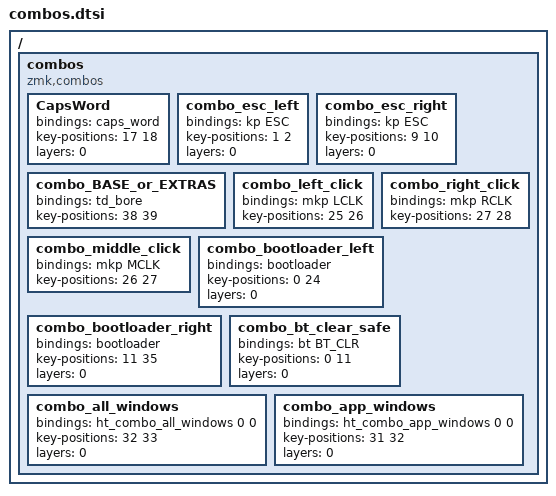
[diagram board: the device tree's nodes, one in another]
/* --- KEY ID LAYOUT --- */
// ╭──────┬──────┬──────┬──────┬──────┬──────╮  ╭──────┬──────┬──────┬──────┬──────┬──────╮
//    00     01     02     03    04      05        06     07     08     09     10     11
// ├──────┼──────┼──────┼──────┼──────┼──────┤  ├──────┼──────┼──────┼──────┼──────┼──────┤
//    12     13     14     15    16      17        18     19     20     21     22     23
// ├──────┼──────┼──────┼──────┼──────┼──────┤  ├──────┼──────┼──────┼──────┼──────┼──────┤
//    24     25     26     27    28      29        30     31     32     33     34     35
// ╰──────┴──────┴──────┼──────┼──────┼──────┤  ├──────┼──────┼──────┴──────┴──────┴──────╯
//                         36     37     38        39     40
//                      ╰──────┴──────┴──────╯  ╰──────┴──────╯

/ {
    combos {
        compatible = "zmk,combos";

        CapsWord {
            bindings = <&caps_word>;
            key-positions = <17 18>;
            layers = <0>;
        };

        combo_esc_left {
            bindings = <&kp ESC>;
            key-positions = <1 2>;
            layers = <0>;
        };

        combo_esc_right {
            bindings = <&kp ESC>;
            key-positions = <9 10>;
            layers = <0>;
        };

        combo_BASE_or_EXTRAS {
            bindings = <&td_bore>;
            key-positions = <38 39>;
        };
        
        combo_left_click {
            bindings = <&mkp LCLK>;
            key-positions = <25 26>;
        };
        
        combo_middle_click {
            bindings = <&mkp MCLK>;
            key-positions = <26 27>;
        };

        combo_right_click {
            bindings = <&mkp RCLK>;
            key-positions = <27 28>;
        };

        combo_bootloader_left {
            bindings = <&bootloader>;
            key-positions = <0 24>;
            layers = <0>;
        };

        combo_bootloader_right {
            bindings = <&bootloader>;
            key-positions = <11 35>;
            layers = <0>;
        };

        combo_bt_clear_safe {
            bindings = <&bt BT_CLR>;
            key-positions = <0 11>;
            layers = <0>;
        };

        combo_all_windows {
            bindings = <&ht_combo_all_windows 0 0>;
            key-positions = <32 33>;
            layers = <0>;
        };

        combo_app_windows {
            // KDE Present Windows (current app/window class).
            bindings = <&ht_combo_app_windows 0 0>;
            key-positions = <31 32>;
            layers = <0>;
        };
    };
};
